# LargeDummyDevice register map
File version: 1.0
Registers are 32-bit, read-write, no defined reset value unless marked. A register's access mark holds for its fields unless they carry their own. Offsets are from the block's base; [hi:lo] are bit positions.

## PERIPHERAL_38
Base 0x40025000
0x04 REG_1 — Register 1
  [24:23] FIELD_5, [23:21] FIELD_3, [20] FIELD_1, [23:20] FIELD_4, [15] FIELD_2
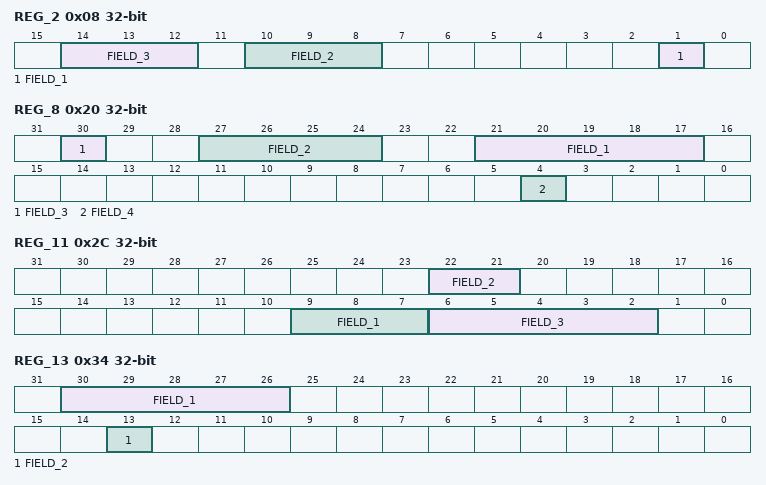
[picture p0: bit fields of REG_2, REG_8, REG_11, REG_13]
0x08 REG_2 — Register 2
  [14:12] FIELD_3, [10:8] FIELD_2, [1] FIELD_1
0x0C REG_3 — Register 3
  [31] FIELD_19, [30:29] FIELD_28, [32:28] FIELD_6, [29:28] FIELD_15, [31:27] FIELD_7, [26] FIELD_3, [27:26] FIELD_13, [27:25] FIELD_22, [28:25] FIELD_26, [26:23] FIELD_10, [22] FIELD_2, [24:22] FIELD_11, [24:21] FIELD_27, [20:19] FIELD_4, [22:18] FIELD_25, [18:17] FIELD_12, [17] FIELD_24, [17:16] FIELD_14, [14:12] FIELD_23, [15:11] FIELD_21, [9:7] FIELD_5, [8:7] FIELD_8, [11:7] FIELD_9, [10:7] FIELD_20, [10:6] FIELD_16, [7:5] FIELD_1, [5:3] FIELD_18, [2:0] FIELD_17, [3:0] FIELD_29
0x10 REG_4 — Register 4
  [34:31] FIELD_1, [29:28] FIELD_13, [27] FIELD_9, [28:24] FIELD_3, [25:23] FIELD_14, [22] FIELD_8, [23:21] FIELD_4, [24:21] FIELD_7, [20:19] FIELD_2, [18:17] FIELD_5, [19:15] FIELD_6, [14:11] FIELD_10, [12:8] FIELD_11, [1] FIELD_12
0x14 REG_5 — Register 5
  [25:24] FIELD_9, [24:22] FIELD_4, [21:20] FIELD_3, [22:20] FIELD_8, [21:18] FIELD_2, [19:18] FIELD_7, [17:16] FIELD_1, [17:14] FIELD_5, [7:4] FIELD_6
0x18 REG_6 — Register 6
  [32:31] FIELD_5, [31:30] FIELD_11, [29] FIELD_6, [27:24] FIELD_2, [25:22] FIELD_9, [21:20] FIELD_13, [22:18] FIELD_3, [20:17] FIELD_4, [15:14] FIELD_8, [11] FIELD_7, [11] FIELD_14, [12:10] FIELD_12, [9:6] FIELD_1, [5:1] FIELD_10
0x1C REG_7 — Register 7
  [34:30] FIELD_5, [32:28] FIELD_4, [28] FIELD_12, [27:25] FIELD_11, [29:25] FIELD_14, [22] FIELD_23, [24:21] FIELD_21, [22:21] FIELD_22, [22:19] FIELD_24, [21:17] FIELD_18, [20:16] FIELD_15, [16:15] FIELD_10, [17:13] FIELD_16, [13:12] FIELD_6, [16:12] FIELD_8, [14:11] FIELD_17, [8] FIELD_20, [8:6] FIELD_9, [10:6] FIELD_19, [7:4] FIELD_2, [4] FIELD_3, [8:4] FIELD_7, [3:2] FIELD_13, [1] FIELD_1
0x20 REG_8 — Register 8
  [30] FIELD_3, [27:24] FIELD_2, [21:17] FIELD_1, [4] FIELD_4
0x24 REG_9 — Register 9
  [10:9] FIELD_1
0x28 REG_10 — Register 10
  [32:29] FIELD_4, [24:20] FIELD_2, [21:17] FIELD_7, [15] FIELD_1, [19:15] FIELD_8, [15:13] FIELD_6, [13:10] FIELD_9, [9:6] FIELD_5, [7:5] FIELD_3
0x2C REG_11 — Register 11
  [22:21] FIELD_2, [9:7] FIELD_1, [6:2] FIELD_3
0x30 REG_12 — Register 12
  [30:29] FIELD_2, [32:28] FIELD_1, [28] FIELD_20, [30:28] FIELD_23, [28:27] FIELD_13, [27:24] FIELD_16, [22] FIELD_4, [25:21] FIELD_6, [25:21] FIELD_9, [22:21] FIELD_25, [20:19] FIELD_22, [19:16] FIELD_18, [17:14] FIELD_7, [15:13] FIELD_8, [10] FIELD_15, [11:10] FIELD_21, [13:9] FIELD_24, [12:8] FIELD_11, [8] FIELD_14, [10:7] FIELD_10, [8:6] FIELD_17, [9:5] FIELD_5, [7:4] FIELD_3, [3:1] FIELD_12, [5:1] FIELD_19
0x34 REG_13 — Register 13
  [30:26] FIELD_1, [13] FIELD_2
0x38 REG_14 — Register 14
  [35:31] FIELD_12, [34:31] FIELD_29, [35:31] FIELD_31, [32:30] FIELD_26, [28] FIELD_1, [31:28] FIELD_27, [29:28] FIELD_28, [31:27] FIELD_18, [24] FIELD_3, [21] FIELD_10, [24:21] FIELD_22, [17] FIELD_8, [18:15] FIELD_11, [19:15] FIELD_13, [15] FIELD_23, [18:14] FIELD_20, [16:13] FIELD_4, [17:13] FIELD_5, [17:13] FIELD_30, [9] FIELD_6, [9] FIELD_17, [8:7] FIELD_16, [8:5] FIELD_2, [7:5] FIELD_21, [2] FIELD_7, [5:2] FIELD_14, [3:2] FIELD_15, [5:2] FIELD_24, [6:2] FIELD_25, [0] FIELD_9, [2:0] FIELD_19
0x3C REG_15 — Register 15
  [26:24] FIELD_4, [28:24] FIELD_7, [23] FIELD_14, [25:21] FIELD_2, [24:20] FIELD_8, [19:17] FIELD_11, [16] FIELD_6, [19:15] FIELD_9, [19:15] FIELD_13, [19:15] FIELD_15, [14:11] FIELD_10, [12:10] FIELD_1, [12:10] FIELD_12, [6:5] FIELD_5, [1:0] FIELD_3
0x40 REG_16 — Register 16
  [27:26] FIELD_11, [26] FIELD_17, [27:24] FIELD_9, [24:23] FIELD_2, [26:22] FIELD_1, [20:19] FIELD_12, [20:18] FIELD_5, [22:18] FIELD_16, [19:17] FIELD_7, [16:15] FIELD_4, [16:15] FIELD_6, [18:15] FIELD_13, [15:14] FIELD_15, [12:10] FIELD_18, [10:8] FIELD_8, [10:8] FIELD_10, [9:8] FIELD_14, [5:4] FIELD_3
0x44 REG_17 — Register 17
  [31] FIELD_10, [29:26] FIELD_15, [26:25] FIELD_3, [23] FIELD_13, [25:21] FIELD_5, [22:19] FIELD_9, [23:19] FIELD_11, [21:18] FIELD_1, [22:18] FIELD_6, [15:14] FIELD_8, [15:13] FIELD_7, [14:13] FIELD_16, [10] FIELD_14, [9:7] FIELD_2, [5:3] FIELD_4, [7:3] FIELD_12
0x48 REG_18 — Register 18
  [30:28] FIELD_2, [19] FIELD_1, [21:19] FIELD_3, [12:8] FIELD_4
0x4C REG_19 — Register 19
  [32:29] FIELD_21, [31:28] FIELD_24, [31:27] FIELD_6, [31:27] FIELD_18, [28:26] FIELD_23, [27:25] FIELD_2, [25:21] FIELD_19, [19:17] FIELD_1, [18:17] FIELD_25, [18:16] FIELD_3, [17:16] FIELD_4, [18:15] FIELD_7, [16:14] FIELD_16, [16:13] FIELD_8, [15:12] FIELD_13, [13:12] FIELD_17, [11] FIELD_11, [15:11] FIELD_12, [7] FIELD_5, [7] FIELD_10, [7:6] FIELD_22, [5:4] FIELD_9, [4] FIELD_14, [6:4] FIELD_15, [6:2] FIELD_20
0x50 REG_20 — Register 20
  [32:29] FIELD_22, [30:28] FIELD_17, [30:27] FIELD_2, [30:26] FIELD_10, [29:26] FIELD_13, [26] FIELD_18, [29:25] FIELD_5, [25:24] FIELD_6, [27:24] FIELD_14, [25:23] FIELD_7, [27:23] FIELD_28, [22] FIELD_12, [25:22] FIELD_25, [21] FIELD_3, [20:19] FIELD_9, [20:19] FIELD_19, [17] FIELD_1, [19:16] FIELD_8, [16:15] FIELD_16, [18:15] FIELD_20, [14:11] FIELD_4, [15:11] FIELD_31, [12:10] FIELD_23, [12:10] FIELD_24, [13:9] FIELD_29, [11:9] FIELD_30, [9:5] FIELD_15, [6:3] FIELD_11, [2] FIELD_27, [5:1] FIELD_21, [4:1] FIELD_26
0x54 REG_21 — Register 21
  [35:31] FIELD_10, [31:30] FIELD_4, [31:28] FIELD_13, [23] FIELD_7, [21:19] FIELD_3, [16:15] FIELD_12, [15:14] FIELD_6, [18:14] FIELD_14, [13:10] FIELD_5, [9:8] FIELD_8, [4:3] FIELD_2, [6:3] FIELD_9, [6:2] FIELD_1, [6:2] FIELD_11, [3:2] FIELD_15
0x58 REG_22 — Register 22
  [32:28] FIELD_8, [22] FIELD_6, [22] FIELD_7, [23:20] FIELD_2, [20:19] FIELD_1, [20:18] FIELD_4, [22:18] FIELD_10, [16:12] FIELD_5, [9:7] FIELD_3, [6:3] FIELD_13, [3:1] FIELD_12, [3:0] FIELD_9, [4:0] FIELD_11
0x5C REG_23 — Register 23
  [34:31] FIELD_3, [34:31] FIELD_19, [29] FIELD_6, [30:29] FIELD_8, [28] FIELD_14, [30:28] FIELD_15, [31:27] FIELD_17, [29:27] FIELD_22, [26:22] FIELD_9, [26:22] FIELD_11, [21] FIELD_16, [25:21] FIELD_25, [22:20] FIELD_1, [21:19] FIELD_7, [17:15] FIELD_20, [17:14] FIELD_12, [15:14] FIELD_21, [16:12] FIELD_18, [15:12] FIELD_23, [10:9] FIELD_24, [11:9] FIELD_26, [8:7] FIELD_2, [9:7] FIELD_13, [6:5] FIELD_4, [3] FIELD_5, [6:2] FIELD_10, [2:0] FIELD_27
0x60 REG_24 — Register 24
  [34:30] FIELD_3, [33:29] FIELD_1, [18:16] FIELD_2, [7:3] FIELD_4, [2:1] FIELD_5
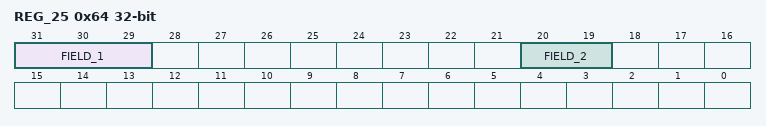
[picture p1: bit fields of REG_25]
0x64 REG_25 — Register 25
  [31:29] FIELD_1, [20:19] FIELD_2
0x68 REG_26 — Register 26
  [32:31] FIELD_1, [32:31] FIELD_2, [32:28] FIELD_17, [28:27] FIELD_21, [26] FIELD_11, [26:25] FIELD_13, [28:24] FIELD_26, [24:22] FIELD_23, [23:19] FIELD_8, [20:17] FIELD_5, [18:16] FIELD_22, [16:14] FIELD_12, [16:13] FIELD_9, [15:11] FIELD_4, [12:11] FIELD_15, [9:8] FIELD_25, [8:7] FIELD_7, [7] FIELD_10, [6] FIELD_14, [9:6] FIELD_19, [6:5] FIELD_3, [7:5] FIELD_16, [4] FIELD_18, [5:1] FIELD_20, [5:1] FIELD_24, [0] FIELD_6
0x6C REG_27 — Register 27
  [27:25] FIELD_4, [22:20] FIELD_7, [21:18] FIELD_1, [13:9] FIELD_6, [8:6] FIELD_2, [4:3] FIELD_3, [2] FIELD_5
0x70 REG_28 — Register 28
  [29:27] FIELD_5, [22:21] FIELD_4, [8] FIELD_1, [9:8] FIELD_3, [10:7] FIELD_2, [6:3] FIELD_6
0x74 REG_29 — Register 29
  [30:29] FIELD_14, [30:28] FIELD_10, [30:27] FIELD_7, [28:27] FIELD_11, [26] FIELD_5, [26:25] FIELD_2, [25:22] FIELD_9, [26:22] FIELD_12, [25:21] FIELD_15, [19:17] FIELD_4, [9:8] FIELD_6, [8:6] FIELD_1, [9:5] FIELD_13, [4:3] FIELD_3, [4:2] FIELD_16, [0] FIELD_8
0x78 REG_30 — Register 30
  [33:30] FIELD_10, [33:29] FIELD_13, [27:26] FIELD_9, [28:25] FIELD_12, [25:22] FIELD_8, [24:22] FIELD_11, [23:20] FIELD_17, [18:17] FIELD_5, [20:17] FIELD_6, [16] FIELD_19, [17:15] FIELD_14, [17:15] FIELD_16, [15:12] FIELD_7, [8] FIELD_2, [8] FIELD_18, [7:4] FIELD_3, [8:4] FIELD_15, [5:3] FIELD_1, [4:0] FIELD_4
0x7C REG_31 — Register 31
  [32:28] FIELD_3, [12:11] FIELD_1, [11:8] FIELD_4, [9:7] FIELD_2
0x80 REG_32 — Register 32
  [35:31] FIELD_14, [33:30] FIELD_1, [32:30] FIELD_2, [30:26] FIELD_11, [26:24] FIELD_15, [27:23] FIELD_6, [19] FIELD_9, [17] FIELD_8, [17] FIELD_13, [15:14] FIELD_10, [14] FIELD_16, [15:13] FIELD_12, [12:11] FIELD_5, [12:10] FIELD_4, [8:4] FIELD_3, [3] FIELD_7
0x84 REG_33 — Register 33
  [34:31] FIELD_5, [30] FIELD_4, [30] FIELD_10, [33:29] FIELD_7, [28] FIELD_9, [30:27] FIELD_16, [23:22] FIELD_2, [23:22] FIELD_6, [25:22] FIELD_15, [21:19] FIELD_18, [12] FIELD_8, [13:9] FIELD_17, [5:4] FIELD_13, [4:3] FIELD_12, [7:3] FIELD_14, [1] FIELD_1, [3:1] FIELD_3, [4:0] FIELD_11
0x88 REG_34 — Register 34
  [23:22] FIELD_8, [17:16] FIELD_11, [15] FIELD_9, [18:14] FIELD_5, [15:13] FIELD_2, [5:4] FIELD_1, [4] FIELD_10, [3] FIELD_4, [2:1] FIELD_3, [1] FIELD_7, [2:0] FIELD_6
0x8C REG_35 — Register 35
  [27:23] FIELD_8, [25:21] FIELD_5, [21:20] FIELD_1, [18:14] FIELD_3, [10:9] FIELD_9, [12:8] FIELD_4, [10:8] FIELD_7, [6] FIELD_2, [6:5] FIELD_6
0x90 REG_36 — Register 36
  [35:31] FIELD_14, [34:31] FIELD_18, [31:29] FIELD_7, [31:28] FIELD_15, [31:28] FIELD_19, [26:25] FIELD_13, [22] FIELD_8, [22] FIELD_11, [26:22] FIELD_23, [23:20] FIELD_17, [20:19] FIELD_20, [22:18] FIELD_1, [17] FIELD_12, [17:16] FIELD_16, [17:16] FIELD_21, [19:15] FIELD_5, [14:12] FIELD_6, [11:8] FIELD_4, [10:8] FIELD_9, [11:8] FIELD_22, [10:6] FIELD_3, [7:6] FIELD_10, [4:1] FIELD_2
